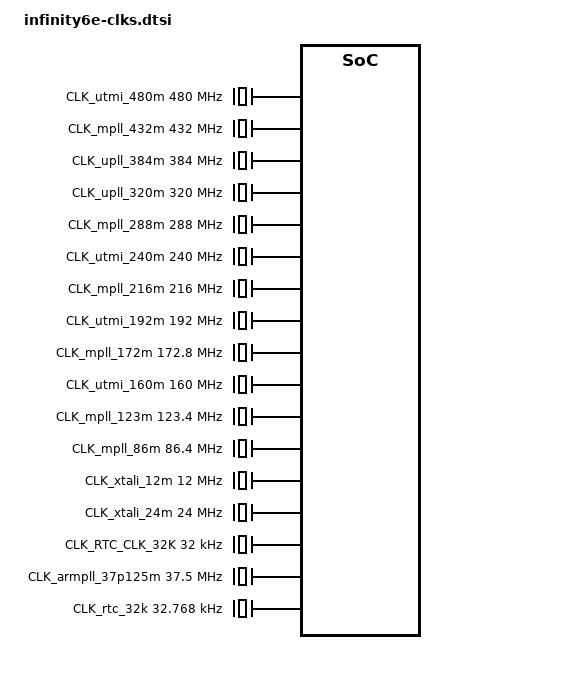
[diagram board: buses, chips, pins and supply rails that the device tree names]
/*
* infinity6e-clks.dtsi- Sigmastar
*
* Copyright (c) [2019~2020] SigmaStar Technology.
*
*
* This software is licensed under the terms of the GNU General Public
* License version 2, as published by the Free Software Foundation, and
* may be copied, distributed, and modified under those terms.
*
* This program is distributed in the hope that it will be useful,
* but WITHOUT ANY WARRANTY; without even the implied warranty of
* MERCHANTABILITY or FITNESS FOR A PARTICULAR PURPOSE.  See the
* GNU General Public License version 2 for more details.
*
*/
/* generated by CLK_DT_GEN_5.1 */
/* CLK FILENAME: I6e/iNfinity6e_Clock_Table_0903.xls */
/* REG FILENAME: I6e/iNfinity6e_reg_CLKGEN.xls, I6e/iNfinity6e_reg_pm_sleep.xls, I6e/iNfinity6e_reg_block.xls, I6e/iNfinity6e_reg_chiptop.xls */

CLK_VOID: CLK_VOID {
    #clock-cells = <0>;
    compatible = "fixed-clock";
    clock-frequency = <1>;
};

CLK_utmi_480m: CLK_utmi_480m {
    #clock-cells = <0>;
    compatible = "fixed-clock";
    clock-frequency = <480000000>;
};

CLK_mpll_432m: CLK_mpll_432m {
    #clock-cells = <0>;
    compatible = "fixed-clock";
    clock-frequency = <432000000>;
};

CLK_upll_384m: CLK_upll_384m {
    #clock-cells = <0>;
    compatible = "fixed-clock";
    clock-frequency = <384000000>;
};

CLK_upll_320m: CLK_upll_320m {
    #clock-cells = <0>;
    compatible = "fixed-clock";
    clock-frequency = <320000000>;
};

CLK_mpll_288m: CLK_mpll_288m {
    #clock-cells = <0>;
    compatible = "fixed-clock";
    clock-frequency = <288000000>;
};

CLK_utmi_240m: CLK_utmi_240m {
    #clock-cells = <0>;
    compatible = "fixed-clock";
    clock-frequency = <240000000>;
};

CLK_mpll_216m: CLK_mpll_216m {
    #clock-cells = <0>;
    compatible = "fixed-clock";
    clock-frequency = <216000000>;
};

CLK_utmi_192m: CLK_utmi_192m {
    #clock-cells = <0>;
    compatible = "fixed-clock";
    clock-frequency = <192000000>;
};

CLK_mpll_172m: CLK_mpll_172m {
    #clock-cells = <0>;
    compatible = "fixed-clock";
    clock-frequency = <172800000>;
};

CLK_utmi_160m: CLK_utmi_160m {
    #clock-cells = <0>;
    compatible = "fixed-clock";
    clock-frequency = <160000000>;
};

CLK_mpll_123m: CLK_mpll_123m {
    #clock-cells = <0>;
    compatible = "fixed-clock";
    clock-frequency = <123400000>;
};

CLK_mpll_86m: CLK_mpll_86m {
    #clock-cells = <0>;
    compatible = "fixed-clock";
    clock-frequency = <86400000>;
};

CLK_mpll_288m_div2: CLK_mpll_288m_div2 {
    #clock-cells = <0>;
    compatible = "fixed-factor-clock";
    clocks = <&CLK_mpll_288m>;
    clock-div = <2>;
    clock-mult = <1>;
};

CLK_mpll_288m_div4: CLK_mpll_288m_div4 {
    #clock-cells = <0>;
    compatible = "fixed-factor-clock";
    clocks = <&CLK_mpll_288m>;
    clock-div = <4>;
    clock-mult = <1>;
};

CLK_mpll_288m_div8: CLK_mpll_288m_div8 {
    #clock-cells = <0>;
    compatible = "fixed-factor-clock";
    clocks = <&CLK_mpll_288m>;
    clock-div = <8>;
    clock-mult = <1>;
};

CLK_mpll_216m_div2: CLK_mpll_216m_div2 {
    #clock-cells = <0>;
    compatible = "fixed-factor-clock";
    clocks = <&CLK_mpll_216m>;
    clock-div = <2>;
    clock-mult = <1>;
};

CLK_mpll_216m_div4: CLK_mpll_216m_div4 {
    #clock-cells = <0>;
    compatible = "fixed-factor-clock";
    clocks = <&CLK_mpll_216m>;
    clock-div = <4>;
    clock-mult = <1>;
};

CLK_mpll_216m_div8: CLK_mpll_216m_div8 {
    #clock-cells = <0>;
    compatible = "fixed-factor-clock";
    clocks = <&CLK_mpll_216m>;
    clock-div = <8>;
    clock-mult = <1>;
};

CLK_mpll_123m_div2: CLK_mpll_123m_div2 {
    #clock-cells = <0>;
    compatible = "fixed-factor-clock";
    clocks = <&CLK_mpll_123m>;
    clock-div = <2>;
    clock-mult = <1>;
};

CLK_mpll_86m_div2: CLK_mpll_86m_div2 {
    #clock-cells = <0>;
    compatible = "fixed-factor-clock";
    clocks = <&CLK_mpll_86m>;
    clock-div = <2>;
    clock-mult = <1>;
};

CLK_mpll_86m_div4: CLK_mpll_86m_div4 {
    #clock-cells = <0>;
    compatible = "fixed-factor-clock";
    clocks = <&CLK_mpll_86m>;
    clock-div = <4>;
    clock-mult = <1>;
};

CLK_mpll_86m_div16: CLK_mpll_86m_div16 {
    #clock-cells = <0>;
    compatible = "fixed-factor-clock";
    clocks = <&CLK_mpll_86m>;
    clock-div = <16>;
    clock-mult = <1>;
};

CLK_utmi_192m_div4: CLK_utmi_192m_div4 {
    #clock-cells = <0>;
    compatible = "fixed-factor-clock";
    clocks = <&CLK_utmi_192m>;
    clock-div = <4>;
    clock-mult = <1>;
};

CLK_utmi_160m_div4: CLK_utmi_160m_div4 {
    #clock-cells = <0>;
    compatible = "fixed-factor-clock";
    clocks = <&CLK_utmi_160m>;
    clock-div = <4>;
    clock-mult = <1>;
};

CLK_utmi_160m_div5: CLK_utmi_160m_div5 {
    #clock-cells = <0>;
    compatible = "fixed-factor-clock";
    clocks = <&CLK_utmi_160m>;
    clock-div = <5>;
    clock-mult = <1>;
};

CLK_utmi_160m_div8: CLK_utmi_160m_div8 {
    #clock-cells = <0>;
    compatible = "fixed-factor-clock";
    clocks = <&CLK_utmi_160m>;
    clock-div = <8>;
    clock-mult = <1>;
};

CLK_xtali_12m: CLK_xtali_12m {
    #clock-cells = <0>;
    compatible = "fixed-clock";
    clock-frequency = <12000000>;
};

CLK_xtali_12m_div2: CLK_xtali_12m_div2 {
    #clock-cells = <0>;
    compatible = "fixed-factor-clock";
    clocks = <&CLK_xtali_12m>;
    clock-div = <2>;
    clock-mult = <1>;
};

CLK_xtali_12m_div4: CLK_xtali_12m_div4 {
    #clock-cells = <0>;
    compatible = "fixed-factor-clock";
    clocks = <&CLK_xtali_12m>;
    clock-div = <4>;
    clock-mult = <1>;
};

CLK_xtali_12m_div8: CLK_xtali_12m_div8 {
    #clock-cells = <0>;
    compatible = "fixed-factor-clock";
    clocks = <&CLK_xtali_12m>;
    clock-div = <8>;
    clock-mult = <1>;
};

CLK_xtali_12m_div16: CLK_xtali_12m_div16 {
    #clock-cells = <0>;
    compatible = "fixed-factor-clock";
    clocks = <&CLK_xtali_12m>;
    clock-div = <16>;
    clock-mult = <1>;
};

CLK_xtali_12m_div40: CLK_xtali_12m_div40 {
    #clock-cells = <0>;
    compatible = "fixed-factor-clock";
    clocks = <&CLK_xtali_12m>;
    clock-div = <40>;
    clock-mult = <1>;
};

CLK_xtali_12m_div64: CLK_xtali_12m_div64 {
    #clock-cells = <0>;
    compatible = "fixed-factor-clock";
    clocks = <&CLK_xtali_12m>;
    clock-div = <64>;
    clock-mult = <1>;
};

CLK_xtali_12m_div128: CLK_xtali_12m_div128 {
    #clock-cells = <0>;
    compatible = "fixed-factor-clock";
    clocks = <&CLK_xtali_12m>;
    clock-div = <128>;
    clock-mult = <1>;
};

CLK_xtali_24m: CLK_xtali_24m {
    #clock-cells = <0>;
    compatible = "fixed-clock";
    clock-frequency = <24000000>;
};

CLK_RTC_CLK_32K: CLK_RTC_CLK_32K {
    #clock-cells = <0>;
    compatible = "fixed-clock";
    clock-frequency = <32000>;
};

CLK_pm_riu_w_clk_in: CLK_pm_riu_w_clk_in {
    #clock-cells = <0>;
    compatible = "fixed-clock";
    clock-frequency = <108000000>;
};

CLK_miupll_clk: CLK_miupll_clk {
    #clock-cells = <0>;
    compatible = "fixed-clock";
    clock-frequency = <400000000>;
};

CLK_ddrpll_clk: CLK_ddrpll_clk {
    #clock-cells = <0>;
    compatible = "fixed-clock";
    clock-frequency = <2133000000>;
};

CLK_lpll_clk: CLK_lpll_clk {
    #clock-cells = <0>;
    compatible = "fixed-clock";
    clock-frequency = <100000000>;
};

CLK_ven_pll: CLK_ven_pll {
    #clock-cells = <0>;
    compatible = "sstar,complex-clock";
    clocks = <&CLK_xtali_24m>;
};
CLK_ven_pll_div6: CLK_ven_pll_div6 {
    #clock-cells = <0>;
    compatible = "fixed-clock";
    clock-frequency = <104000000>;
};

CLK_lpll_div2: CLK_lpll_div2 {
    #clock-cells = <0>;
    compatible = "fixed-clock";
    clock-frequency = <50000000>;
};

CLK_lpll_div4: CLK_lpll_div4 {
    #clock-cells = <0>;
    compatible = "fixed-clock";
    clock-frequency = <25000000>;
};

CLK_lpll_div8: CLK_lpll_div8 {
    #clock-cells = <0>;
    compatible = "fixed-clock";
    clock-frequency = <12500000>;
};

CLK_armpll_37p125m: CLK_armpll_37p125m {
    #clock-cells = <0>;
    compatible = "fixed-clock";
    clock-frequency = <37500000>;
};

CLK_riu_w_clk_in: CLK_riu_w_clk_in {
    #clock-cells = <0>;
    compatible = "fixed-factor-clock";
    clocks = <&CLK_mcu>;
    clock-div = <1>;
    clock-mult = <1>;
};

CLK_riu_w_clk_top: CLK_riu_w_clk_top {
    #clock-cells = <0>;
    compatible = "fixed-factor-clock";
    clocks = <&CLK_mcu>;
    clock-div = <1>;
    clock-mult = <1>;
};

CLK_riu_w_clk_sc_gp: CLK_riu_w_clk_sc_gp {
    #clock-cells = <0>;
    compatible = "fixed-factor-clock";
    clocks = <&CLK_mcu>;
    clock-div = <1>;
    clock-mult = <1>;
};

CLK_riu_w_clk_vhe_gp: CLK_riu_w_clk_vhe_gp {
    #clock-cells = <0>;
    compatible = "fixed-factor-clock";
    clocks = <&CLK_mcu>;
    clock-div = <1>;
    clock-mult = <1>;
};

CLK_riu_w_clk_hemcu_gp: CLK_riu_w_clk_hemcu_gp {
    #clock-cells = <0>;
    compatible = "fixed-factor-clock";
    clocks = <&CLK_mcu>;
    clock-div = <1>;
    clock-mult = <1>;
};

CLK_riu_w_clk_mipi_if_gp: CLK_riu_w_clk_mipi_if_gp {
    #clock-cells = <0>;
    compatible = "fixed-factor-clock";
    clocks = <&CLK_mcu>;
    clock-div = <1>;
    clock-mult = <1>;
};

CLK_riu_w_clk_mcu_if_gp: CLK_riu_w_clk_mcu_if_gp {
    #clock-cells = <0>;
    compatible = "fixed-factor-clock";
    clocks = <&CLK_mcu>;
    clock-div = <1>;
    clock-mult = <1>;
};

CLK_fuart0_synth_out: CLK_fuart0_synth_out {
    #clock-cells = <0>;
    compatible = "fixed-clock";
    clock-frequency = <432000000>;
};

CLK_miu_p: CLK_miu_p {
    #clock-cells = <0>;
    compatible = "fixed-factor-clock";
    clocks = <&CLK_miu>;
    clock-div = <1>;
    clock-mult = <1>;
};

CLK_mspi0_p: CLK_mspi0_p {
    #clock-cells = <0>;
    compatible = "fixed-factor-clock";
    clocks = <&CLK_mspi0>;
    clock-div = <1>;
    clock-mult = <1>;
};

CLK_mspi1_p: CLK_mspi1_p {
    #clock-cells = <0>;
    compatible = "fixed-factor-clock";
    clocks = <&CLK_mspi1>;
    clock-div = <1>;
    clock-mult = <1>;
};

CLK_miu_vhe_gp_p: CLK_miu_vhe_gp_p {
    #clock-cells = <0>;
    compatible = "fixed-factor-clock";
    clocks = <&CLK_miu>;
    clock-div = <1>;
    clock-mult = <1>;
};

CLK_miu_sc_gp_p: CLK_miu_sc_gp_p {
    #clock-cells = <0>;
    compatible = "fixed-factor-clock";
    clocks = <&CLK_miu>;
    clock-div = <1>;
    clock-mult = <1>;
};

CLK_mcu_p: CLK_mcu_p {
    #clock-cells = <0>;
    compatible = "fixed-factor-clock";
    clocks = <&CLK_mcu>;
    clock-div = <1>;
    clock-mult = <1>;
};

CLK_fclk1_p: CLK_fclk1_p {
    #clock-cells = <0>;
    compatible = "fixed-factor-clock";
    clocks = <&CLK_fclk1>;
    clock-div = <1>;
    clock-mult = <1>;
};

/*
CLK_fclk2_p: CLK_fclk2_p {
    #clock-cells = <0>;
    compatible = "fixed-factor-clock";
    clocks = <&CLK_fclk2>;
    clock-div = <1>;
    clock-mult = <1>;
};
*/

CLK_sdio_p: CLK_sdio_p {
    #clock-cells = <0>;
    compatible = "fixed-factor-clock";
    clocks = <&CLK_sdio>;
    clock-div = <1>;
    clock-mult = <1>;
};

CLK_tck_buf: CLK_tck_buf {
    #clock-cells = <0>;
    compatible = "fixed-clock";
    clock-frequency = <50000000>;
};

CLK_eth_buf: CLK_eth_buf {
    #clock-cells = <0>;
    compatible = "fixed-clock";
    clock-frequency = <125000000>;
};

CLK_rmii_buf: CLK_rmii_buf {
    #clock-cells = <0>;
    compatible = "fixed-clock";
    clock-frequency = <125000000>;
};

CLK_emac_testrx125_in_lan: CLK_emac_testrx125_in_lan {
    #clock-cells = <0>;
    compatible = "fixed-clock";
    clock-frequency = <125000000>;
};

/*
CLK_imi: CLK_imi {
    #clock-cells = <0>;
    compatible = "fixed-factor-clock";
    clocks = <&CLK_miu_p>;
    clock-div = <1>;
    clock-mult = <1>;
};

CLK_sdio: CLK_sdio {
    #clock-cells = <0>;
    compatible = "fixed-factor-clock";
    clocks = <&CLK_sdio_p>;
    clock-div = <1>;
    clock-mult = <1>;
};
*/
CLK_gop0: CLK_gop0 {
    #clock-cells = <0>;
    compatible = "fixed-factor-clock";
    clocks = <&CLK_fclk1_p>;
    clock-div = <1>;
    clock-mult = <1>;
};
/*
CLK_gop1: CLK_gop1 {
    #clock-cells = <0>;
    compatible = "fixed-factor-clock";
    clocks = <&CLK_fclk1_p>;
    clock-div = <1>;
    clock-mult = <1>;
};

CLK_gop2: CLK_gop2 {
    #clock-cells = <0>;
    compatible = "fixed-factor-clock";
    clocks = <&CLK_fclk2_p>;
    clock-div = <1>;
    clock-mult = <1>;
};

*/
CLK_rtc_32k: CLK_rtc_32k {
    #clock-cells = <0>;
    compatible = "fixed-clock";
    clock-frequency = <32768>;
};

CLK_fro: CLK_fro {
    #clock-cells = <0>;
    compatible = "fixed-clock";
    clock-frequency = <48000000>;
};

CLK_fro_div2: CLK_fro_div2 {
    #clock-cells = <0>;
    compatible = "fixed-factor-clock";
    clocks = <&CLK_fro>;
    clock-div = <2>;
    clock-mult = <1>;
};

CLK_fro_div8: CLK_fro_div8 {
    #clock-cells = <0>;
    compatible = "fixed-factor-clock";
    clocks = <&CLK_fro>;
    clock-div = <8>;
    clock-mult = <1>;
};

CLK_fro_div16: CLK_fro_div16 {
    #clock-cells = <0>;
    compatible = "fixed-factor-clock";
    clocks = <&CLK_fro>;
    clock-div = <16>;
    clock-mult = <1>;
};

CLK_cpupll_clk: CLK_cpupll_clk {
    #clock-cells = <0>;
    compatible = "sstar,complex-clock";
    clocks = <&CLK_mpll_432m>;
};

CLK_utmi: CLK_utmi {
    #clock-cells = <0>;
//    compatible = "sstar,complex-clock";
//    clocks = <&CLK_upll>;
    compatible = "fixed-clock";
    clock-frequency = <480000000>;
};

CLK_bach: CLK_bach {
    #clock-cells = <0>;
    compatible = "sstar,composite-clock";
    clocks = <&CLK_upll_384m>;
    reg = <REG_CKG_BACH_384M_BASE 0x4>;
    //mux-shift = <2>;  //2+REG_CKG_MIU_OFFSET
    //mux-width = <2>;
    gate-shift = <7>;  //0+REG_CKG_MIU_OFFSET
    //glitch-shift = <4>;  //4+REG_CKG_MIU_OFFSET
    //auto-enable = <0>;
};

CLK_miu: CLK_miu {
    #clock-cells = <0>;
    compatible = "sstar,composite-clock";
    clocks = <&CLK_mpll_216m>,<&CLK_miupll_clk>,<&CLK_VOID>,<&CLK_VOID>;
    reg = <REG_CKG_MIU_BASE 0x4>;
    mux-shift = <2>;  //2+REG_CKG_MIU_OFFSET
    mux-width = <2>;
    gate-shift = <0>;  //0+REG_CKG_MIU_OFFSET
    glitch-shift = <4>;  //4+REG_CKG_MIU_OFFSET
    auto-enable = <1>;
};

CLK_miu_boot: CLK_miu_boot {
    #clock-cells = <0>;
    compatible = "sstar,composite-clock";
    clocks = <&CLK_xtali_12m>,<&CLK_miu>;
    reg = <REG_CKG_MIU_BASE 0x4>;
    mux-shift = <2>;  //2+REG_CKG_MIU_OFFSET
    mux-width = <1>;
    gate-shift = <0>;  //0+REG_CKG_MIU_OFFSET
    auto-enable = <1>;
};

CLK_ddr_syn: CLK_ddr_syn {
    #clock-cells = <0>;
    compatible = "sstar,composite-clock";
    clocks = <&CLK_mpll_432m>,<&CLK_mpll_216m>,<&CLK_xtali_12m>,<&CLK_VOID>;
    reg = <REG_CKG_DDR_SYN_BASE 0x4>;
    mux-shift = <2>;  //2+REG_CKG_DDR_SYN_OFFSET
    mux-width = <2>;
    gate-shift = <0>;  //0+REG_CKG_DDR_SYN_OFFSET
    auto-enable = <1>;
};

CLK_miu_rec: CLK_miu_rec {
    #clock-cells = <0>;
    compatible = "sstar,composite-clock";
    clocks = <&CLK_xtali_12m_div8>,<&CLK_xtali_12m_div16>,<&CLK_xtali_12m_div64>,<&CLK_xtali_12m_div128>;
    reg = <REG_CKG_MIU_REC_BASE 0x4>;
    mux-shift = <2>;  //2+REG_CKG_MIU_REC_OFFSET
    mux-width = <2>;
    gate-shift = <0>;  //0+REG_CKG_MIU_REC_OFFSET
    auto-enable = <1>;
};

CLK_mcu: CLK_mcu {
    #clock-cells = <0>;
    compatible = "sstar,composite-clock";
    clocks = <&CLK_mpll_216m>,<&CLK_mpll_432m>,<&CLK_upll_384m>,<&CLK_mpll_216m_div2>;
    reg = <REG_CKG_MCU_BASE 0x4>;
    mux-shift = <2>;  //2+REG_CKG_MCU_OFFSET
    mux-width = <2>;
    gate-shift = <0>;  //0+REG_CKG_MCU_OFFSET
    glitch-shift = <4>;  //4+REG_CKG_MCU_OFFSET
    auto-enable = <1>;
};

CLK_riubrdg: CLK_riubrdg {
    #clock-cells = <0>;
    compatible = "sstar,composite-clock";
    clocks = <&CLK_mcu_p>,<&CLK_VOID>,<&CLK_VOID>,<&CLK_VOID>;
    reg = <REG_CKG_RIUBRDG_BASE 0x4>;
    mux-shift = <10>;  //2+REG_CKG_RIUBRDG_OFFSET
    mux-width = <2>;
    gate-shift = <8>;  //0+REG_CKG_RIUBRDG_OFFSET
    auto-enable = <1>;
};

CLK_bdma: CLK_bdma {
    #clock-cells = <0>;
    compatible = "sstar,composite-clock";
    clocks = <&CLK_miu_p>,<&CLK_VOID>,<&CLK_VOID>,<&CLK_VOID>;
    reg = <REG_CKG_BDMA_BASE 0x4>;
    mux-shift = <2>;  //2+REG_CKG_BDMA_OFFSET
    mux-width = <2>;
    gate-shift = <0>;  //0+REG_CKG_BDMA_OFFSET
    auto-enable = <0>;
};

CLK_spi_arb: CLK_spi_arb {
    #clock-cells = <0>;
    compatible = "sstar,composite-clock";
    clocks = <&CLK_mpll_216m>,<&CLK_mpll_216m_div2>,<&CLK_mpll_86m>,<&CLK_miu_p>;
    reg = <REG_CKG_SPI_ARB_BASE 0x4>;
    mux-shift = <2>;  //2+REG_CKG_SPI_ARB_OFFSET
    mux-width = <2>;
    gate-shift = <0>;  //0+REG_CKG_SPI_ARB_OFFSET
    glitch-shift = <4>;  //4+REG_CKG_SPI_ARB_OFFSET
    auto-enable = <1>;
};

CLK_spi_flash: CLK_spi_flash {
    #clock-cells = <0>;
    compatible = "sstar,composite-clock";
    clocks = <&CLK_xtali_12m>,<&CLK_mpll_216m_div8>,<&CLK_mpll_288m_div8>,<&CLK_ven_pll_div6>,<&CLK_mpll_216m_div4>,<&CLK_mpll_288m_div4>,<&CLK_mpll_86m>,<&CLK_mpll_216m_div2>;
    reg = <REG_CKG_SPI_FLASH_BASE 0x4>;
    mux-shift = <2>;  //2+REG_CKG_SPI_FLASH_OFFSET
    mux-width = <3>;
    gate-shift = <0>;  //0+REG_CKG_SPI_FLASH_OFFSET
    glitch-shift = <5>;  //5+REG_CKG_SPI_FLASH_OFFSET
    auto-enable = <1>;
};

CLK_pwm: CLK_pwm {
    #clock-cells = <0>;
    compatible = "sstar,composite-clock";
    clocks = <&CLK_xtali_12m>,<&CLK_xtali_12m_div2>,<&CLK_xtali_12m_div4>,<&CLK_xtali_12m_div8>,<&CLK_xtali_24m>,<&CLK_mpll_86m>,<&CLK_VOID>,<&CLK_VOID>;
    reg = <REG_CKG_PWM_BASE 0x4>;
    mux-shift = <10>;  //2+REG_CKG_PWM_OFFSET
    mux-width = <3>;
    gate-shift = <8>;  //0+REG_CKG_PWM_OFFSET
    auto-enable = <0>;
};

CLK_uart0: CLK_uart0 {
    #clock-cells = <0>;
    compatible = "sstar,composite-clock";
    clocks = <&CLK_mpll_172m>,<&CLK_mpll_288m_div2>,<&CLK_xtali_12m>,<&CLK_VOID>;
    reg = <REG_CKG_UART0_BASE 0x4>;
    mux-shift = <2>;  //2+REG_CKG_UART0_OFFSET
    mux-width = <2>;
    gate-shift = <0>;  //0+REG_CKG_UART0_OFFSET
    auto-enable = <0>;
};

CLK_uart1: CLK_uart1 {
    #clock-cells = <0>;
    compatible = "sstar,composite-clock";
    clocks = <&CLK_mpll_172m>,<&CLK_mpll_288m_div2>,<&CLK_xtali_12m>,<&CLK_VOID>;
    reg = <REG_CKG_UART1_BASE 0x4>;
    mux-shift = <10>;  //2+REG_CKG_UART1_OFFSET
    mux-width = <2>;
    gate-shift = <8>;  //0+REG_CKG_UART1_OFFSET
    auto-enable = <0>;
};

CLK_fuart0_synth_in: CLK_fuart0_synth_in {
    #clock-cells = <0>;
    compatible = "sstar,composite-clock";
    clocks = <&CLK_mpll_432m>,<&CLK_mpll_216m>,<&CLK_VOID>,<&CLK_VOID>;
    reg = <REG_CKG_FUART0_SYNTH_IN_BASE 0x4>;
    mux-shift = <6>;  //2+REG_CKG_FUART0_SYNTH_IN_OFFSET
    mux-width = <2>;
    gate-shift = <4>;  //0+REG_CKG_FUART0_SYNTH_IN_OFFSET
    auto-enable = <0>;
};

CLK_fuart: CLK_fuart {
    #clock-cells = <0>;
    compatible = "sstar,composite-clock";
    clocks = <&CLK_mpll_172m>,<&CLK_mpll_288m_div2>,<&CLK_xtali_12m>,<&CLK_fuart0_synth_out>;
    reg = <REG_CKG_FUART_BASE 0x4>;
    mux-shift = <2>;  //2+REG_CKG_FUART_OFFSET
    mux-width = <2>;
    gate-shift = <0>;  //0+REG_CKG_FUART_OFFSET
    auto-enable = <0>;
};

CLK_mspi0: CLK_mspi0 {
    #clock-cells = <0>;
    compatible = "sstar,composite-clock";
    clocks = <&CLK_mpll_216m_div2>,<&CLK_mpll_216m_div4>,<&CLK_xtali_12m>,<&CLK_mpll_288m_div2>;
    reg = <REG_CKG_MSPI0_BASE 0x4>;
    mux-shift = <2>;  //2+REG_CKG_MSPI0_OFFSET
    mux-width = <2>;
    gate-shift = <0>;  //0+REG_CKG_MSPI0_OFFSET
    auto-enable = <0>;
};

CLK_mspi1: CLK_mspi1 {
    #clock-cells = <0>;
    compatible = "sstar,composite-clock";
    clocks = <&CLK_mpll_216m_div2>,<&CLK_mpll_216m_div4>,<&CLK_xtali_12m>,<&CLK_mpll_288m_div2>;
    reg = <REG_CKG_MSPI1_BASE 0x4>;
    mux-shift = <10>;  //2+REG_CKG_MSPI1_OFFSET
    mux-width = <2>;
    gate-shift = <8>;  //0+REG_CKG_MSPI1_OFFSET
    auto-enable = <0>;
};

CLK_mspi: CLK_mspi {
    #clock-cells = <0>;
    compatible = "sstar,composite-clock";
    clocks = <&CLK_mspi0_p>,<&CLK_mspi1_p>;
    reg = <REG_CKG_MSPI_BASE 0x4>;
    mux-shift = <14>;  //2+REG_CKG_MSPI_OFFSET
    mux-width = <1>;
    gate-shift = <12>;  //0+REG_CKG_MSPI_OFFSET
    auto-enable = <0>;
};

CLK_miic0: CLK_miic0 {
    #clock-cells = <0>;
    compatible = "sstar,composite-clock";
    clocks = <&CLK_mpll_288m_div4>,<&CLK_mpll_216m_div4>,<&CLK_xtali_12m>,<&CLK_VOID>;
    reg = <REG_CKG_MIIC0_BASE 0x4>;
    mux-shift = <2>;  //2+REG_CKG_MIIC0_OFFSET
    mux-width = <2>;
    gate-shift = <0>;  //0+REG_CKG_MIIC0_OFFSET
    auto-enable = <0>;
};

CLK_miic1: CLK_miic1 {
    #clock-cells = <0>;
    compatible = "sstar,composite-clock";
    clocks = <&CLK_mpll_288m_div4>,<&CLK_mpll_216m_div4>,<&CLK_xtali_12m>,<&CLK_VOID>;
    reg = <REG_CKG_MIIC1_BASE 0x4>;
    mux-shift = <10>;  //2+REG_CKG_MIIC1_OFFSET
    mux-width = <2>;
    gate-shift = <8>;  //0+REG_CKG_MIIC1_OFFSET
    auto-enable = <0>;
};

CLK_miic2: CLK_miic2 {
    #clock-cells = <0>;
    compatible = "sstar,composite-clock";
    clocks = <&CLK_mpll_288m_div4>,<&CLK_mpll_216m_div4>,<&CLK_xtali_12m>,<&CLK_VOID>;
    reg = <REG_CKG_MIIC2_BASE 0x4>;
    mux-shift = <14>;  //2+REG_CKG_MIIC2_OFFSET
    mux-width = <2>;
    gate-shift = <12>;  //0+REG_CKG_MIIC2_OFFSET
    auto-enable = <0>;
};

CLK_bist: CLK_bist {
    #clock-cells = <0>;
    compatible = "sstar,composite-clock";
    clocks = <&CLK_mpll_172m>,<&CLK_mpll_216m_div2>,<&CLK_mpll_216m_div4>,<&CLK_xtali_12m>;
    reg = <REG_CKG_BIST_BASE 0x4>;
    mux-shift = <2>;  //2+REG_CKG_BIST_OFFSET
    mux-width = <2>;
    gate-shift = <0>;  //0+REG_CKG_BIST_OFFSET
    auto-enable = <0>;
};

CLK_pwr_ctl: CLK_pwr_ctl {
    #clock-cells = <0>;
    compatible = "sstar,composite-clock";
    clocks = <&CLK_xtali_12m_div16>,<&CLK_xtali_12m_div8>,<&CLK_xtali_12m>,<&CLK_VOID>;
    reg = <REG_CKG_PWR_CTL_BASE 0x4>;
    mux-shift = <2>;  //2+REG_CKG_PWR_CTL_OFFSET
    mux-width = <2>;
    gate-shift = <0>;  //0+REG_CKG_PWR_CTL_OFFSET
    auto-enable = <0>;
};

CLK_xtali: CLK_xtali {
    #clock-cells = <0>;
    compatible = "sstar,composite-clock";
    clocks = <&CLK_xtali_12m>,<&CLK_VOID>,<&CLK_VOID>,<&CLK_VOID>;
    reg = <REG_CKG_XTALI_BASE 0x4>;
    mux-shift = <2>;  //2+REG_CKG_XTALI_OFFSET
    mux-width = <2>;
    gate-shift = <0>;  //0+REG_CKG_XTALI_OFFSET
    auto-enable = <1>;
};

CLK_live: CLK_live {
    #clock-cells = <0>;
    compatible = "sstar,composite-clock";
    clocks = <&CLK_xtali_12m>,<&CLK_VOID>,<&CLK_VOID>,<&CLK_VOID>;
    reg = <REG_CKG_LIVE_BASE 0x4>;
    mux-shift = <10>;  //2+REG_CKG_LIVE_OFFSET
    mux-width = <2>;
    gate-shift = <8>;  //0+REG_CKG_LIVE_OFFSET
    auto-enable = <1>;
};

CLK_sr00_mclk: CLK_sr00_mclk {
    #clock-cells = <0>;
    compatible = "sstar,composite-clock";
    clocks = <&CLK_mpll_216m_div8>,<&CLK_mpll_288m_div4>,<&CLK_mpll_123m_div2>,<&CLK_mpll_216m_div4>,<&CLK_utmi_192m_div4>,<&CLK_mpll_86m_div2>,<&CLK_mpll_288m_div8>,<&CLK_xtali_24m>,<&CLK_mpll_86m_div4>,<&CLK_xtali_12m>,<&CLK_mpll_86m_div16>,<&CLK_lpll_clk>,<&CLK_lpll_div2>,<&CLK_lpll_div4>,<&CLK_lpll_div8>,<&CLK_armpll_37p125m>;
    reg = <REG_CKG_SR00_MCLK_BASE 0x4>;
    mux-shift = <10>;  //2+REG_CKG_SR00_MCLK_OFFSET
    mux-width = <4>;
    gate-shift = <8>;  //0+REG_CKG_SR00_MCLK_OFFSET
    auto-enable = <0>;
};

CLK_sr01_mclk: CLK_sr01_mclk {
    #clock-cells = <0>;
    compatible = "sstar,composite-clock";
    clocks = <&CLK_mpll_216m_div8>,<&CLK_mpll_288m_div4>,<&CLK_mpll_123m_div2>,<&CLK_mpll_216m_div4>,<&CLK_utmi_192m_div4>,<&CLK_mpll_86m_div2>,<&CLK_mpll_288m_div8>,<&CLK_xtali_24m>,<&CLK_mpll_86m_div4>,<&CLK_xtali_12m>,<&CLK_mpll_86m_div16>,<&CLK_lpll_clk>,<&CLK_lpll_div2>,<&CLK_lpll_div4>,<&CLK_lpll_div8>,<&CLK_armpll_37p125m>;
    reg = <REG_CKG_SR01_MCLK_BASE 0x4>;
    mux-shift = <2>;  //2+REG_CKG_SR01_MCLK_OFFSET
    mux-width = <4>;
    gate-shift = <0>;  //0+REG_CKG_SR01_MCLK_OFFSET
    auto-enable = <0>;
};

CLK_sr1_mclk: CLK_sr1_mclk {
    #clock-cells = <0>;
    compatible = "sstar,composite-clock";
    clocks = <&CLK_mpll_216m_div8>,<&CLK_mpll_288m_div4>,<&CLK_mpll_123m_div2>,<&CLK_mpll_216m_div4>,<&CLK_utmi_192m_div4>,<&CLK_mpll_86m_div2>,<&CLK_mpll_288m_div8>,<&CLK_xtali_24m>,<&CLK_mpll_86m_div4>,<&CLK_xtali_12m>,<&CLK_mpll_86m_div16>,<&CLK_lpll_clk>,<&CLK_lpll_div2>,<&CLK_lpll_div4>,<&CLK_lpll_div8>,<&CLK_armpll_37p125m>;
    reg = <REG_CKG_SR1_MCLK_BASE 0x4>;
    mux-shift = <10>;  //2+REG_CKG_SR1_MCLK_OFFSET
    mux-width = <4>;
    gate-shift = <8>;  //0+REG_CKG_SR1_MCLK_OFFSET
    auto-enable = <0>;
};

CLK_bist_pm: CLK_bist_pm {
    #clock-cells = <0>;
    compatible = "sstar,composite-clock";
    clocks = <&CLK_mpll_216m_div2>,<&CLK_mpll_216m_div4>,<&CLK_mpll_216m_div8>,<&CLK_xtali_12m>;
    reg = <REG_CKG_BIST_PM_BASE 0x4>;
    mux-shift = <10>;  //2+REG_CKG_BIST_PM_OFFSET
    mux-width = <2>;
    gate-shift = <8>;  //0+REG_CKG_BIST_PM_OFFSET
    auto-enable = <0>;
};

CLK_bist_ipu_gp: CLK_bist_ipu_gp {
    #clock-cells = <0>;
    compatible = "sstar,composite-clock";
    clocks = <&CLK_mpll_288m>,<&CLK_mpll_216m>,<&CLK_mpll_172m>,<&CLK_mpll_216m_div2>,<&CLK_mpll_86m>,<&CLK_mpll_216m_div4>,<&CLK_mpll_216m_div8>,<&CLK_xtali_12m>;
    reg = <REG_CKG_BIST_IPU_GP_BASE 0x4>;
    mux-shift = <2>;  //2+REG_CKG_BIST_IPU_GP_OFFSET
    mux-width = <3>;
    gate-shift = <0>;  //0+REG_CKG_BIST_IPU_GP_OFFSET
    auto-enable = <1>;
};

CLK_ipu: CLK_ipu {
    #clock-cells = <0>;
    compatible = "sstar,composite-clock";
    clocks = <&CLK_xtali_12m>,<&CLK_utmi_480m>,<&CLK_mpll_432m>,<&CLK_upll_384m>,<&CLK_upll_320m>,<&CLK_utmi_240m>,<&CLK_mpll_216m>,<&CLK_mpll_123m>;
    reg = <REG_CKG_IPU_BASE 0x4>;
    mux-shift = <2>;  //2+REG_CKG_IPU_OFFSET
    mux-width = <3>;
    gate-shift = <0>;  //0+REG_CKG_IPU_OFFSET
    auto-enable = <0>;
};

CLK_ipuff: CLK_ipuff {
    #clock-cells = <0>;
    compatible = "sstar,composite-clock";
    clocks = <&CLK_mpll_432m>,<&CLK_upll_384m>,<&CLK_upll_320m>,<&CLK_utmi_240m>;
    reg = <REG_CKG_IPUFF_BASE 0x4>;
    mux-shift = <10>;  //2+REG_CKG_IPUFF_OFFSET
    mux-width = <2>;
    gate-shift = <8>;  //0+REG_CKG_IPUFF_OFFSET
    auto-enable = <0>;
};

CLK_bist_usb30_gp: CLK_bist_usb30_gp {
    #clock-cells = <0>;
    compatible = "sstar,composite-clock";
    clocks = <&CLK_mpll_172m>,<&CLK_mpll_216m_div2>,<&CLK_mpll_216m_div4>,<&CLK_xtali_12m>;
    reg = <REG_CKG_BIST_USB30_GP_BASE 0x4>;
    mux-shift = <10>;  //2+REG_CKG_BIST_USB30_GP_OFFSET
    mux-width = <2>;
    gate-shift = <8>;  //0+REG_CKG_BIST_USB30_GP_OFFSET
    auto-enable = <0>;
};

CLK_csi_mac_lptx_top_i_m00: CLK_csi_mac_lptx_top_i_m00 {
    #clock-cells = <0>;
    compatible = "sstar,composite-clock";
    clocks = <&CLK_mpll_216m>,<&CLK_utmi_240m>,<&CLK_mpll_172m>,<&CLK_mpll_288m_div2>,<&CLK_mpll_86m>,<&CLK_utmi_160m_div4>,<&CLK_VOID>,<&CLK_VOID>;
    reg = <REG_CKG_CSI_MAC_LPTX_TOP_I_M00_BASE 0x4>;
    mux-shift = <2>;  //2+REG_CKG_CSI_MAC_LPTX_TOP_I_M00_OFFSET
    mux-width = <3>;
    gate-shift = <0>;  //0+REG_CKG_CSI_MAC_LPTX_TOP_I_M00_OFFSET
    auto-enable = <0>;
};

CLK_csi_mac_top_i_m00: CLK_csi_mac_top_i_m00 {
    #clock-cells = <0>;
    compatible = "sstar,composite-clock";
    clocks = <&CLK_mpll_216m>,<&CLK_utmi_240m>,<&CLK_mpll_172m>,<&CLK_mpll_288m_div2>,<&CLK_mpll_86m>,<&CLK_utmi_160m_div4>,<&CLK_VOID>,<&CLK_VOID>;
    reg = <REG_CKG_CSI_MAC_TOP_I_M00_BASE 0x4>;
    mux-shift = <10>;  //2+REG_CKG_CSI_MAC_TOP_I_M00_OFFSET
    mux-width = <3>;
    gate-shift = <8>;  //0+REG_CKG_CSI_MAC_TOP_I_M00_OFFSET
    auto-enable = <0>;
};

CLK_ns_top_i_m00: CLK_ns_top_i_m00 {
    #clock-cells = <0>;
    compatible = "sstar,composite-clock";
    clocks = <&CLK_mpll_216m>,<&CLK_utmi_240m>,<&CLK_mpll_172m>,<&CLK_mpll_288m_div2>,<&CLK_mpll_86m>,<&CLK_utmi_160m_div4>,<&CLK_VOID>,<&CLK_VOID>;
    reg = <REG_CKG_NS_TOP_I_M00_BASE 0x4>;
    mux-shift = <2>;  //2+REG_CKG_NS_TOP_I_M00_OFFSET
    mux-width = <3>;
    gate-shift = <0>;  //0+REG_CKG_NS_TOP_I_M00_OFFSET
    auto-enable = <0>;
};

CLK_csi_mac_lptx_top_i_m01: CLK_csi_mac_lptx_top_i_m01 {
    #clock-cells = <0>;
    compatible = "sstar,composite-clock";
    clocks = <&CLK_mpll_216m>,<&CLK_utmi_240m>,<&CLK_mpll_172m>,<&CLK_mpll_288m_div2>,<&CLK_mpll_86m>,<&CLK_utmi_160m_div4>,<&CLK_VOID>,<&CLK_VOID>;
    reg = <REG_CKG_CSI_MAC_LPTX_TOP_I_M01_BASE 0x4>;
    mux-shift = <10>;  //2+REG_CKG_CSI_MAC_LPTX_TOP_I_M01_OFFSET
    mux-width = <3>;
    gate-shift = <8>;  //0+REG_CKG_CSI_MAC_LPTX_TOP_I_M01_OFFSET
    auto-enable = <0>;
};

CLK_csi_mac_top_i_m01: CLK_csi_mac_top_i_m01 {
    #clock-cells = <0>;
    compatible = "sstar,composite-clock";
    clocks = <&CLK_mpll_216m>,<&CLK_utmi_240m>,<&CLK_mpll_172m>,<&CLK_mpll_288m_div2>,<&CLK_mpll_86m>,<&CLK_utmi_160m_div4>,<&CLK_VOID>,<&CLK_VOID>;
    reg = <REG_CKG_CSI_MAC_TOP_I_M01_BASE 0x4>;
    mux-shift = <2>;  //2+REG_CKG_CSI_MAC_TOP_I_M01_OFFSET
    mux-width = <3>;
    gate-shift = <0>;  //0+REG_CKG_CSI_MAC_TOP_I_M01_OFFSET
    auto-enable = <0>;
};

CLK_ns_top_i_m01: CLK_ns_top_i_m01 {
    #clock-cells = <0>;
    compatible = "sstar,composite-clock";
    clocks = <&CLK_mpll_216m>,<&CLK_utmi_240m>,<&CLK_mpll_172m>,<&CLK_mpll_288m_div2>,<&CLK_mpll_86m>,<&CLK_utmi_160m_div4>,<&CLK_VOID>,<&CLK_VOID>;
    reg = <REG_CKG_NS_TOP_I_M01_BASE 0x4>;
    mux-shift = <10>;  //2+REG_CKG_NS_TOP_I_M01_OFFSET
    mux-width = <3>;
    gate-shift = <8>;  //0+REG_CKG_NS_TOP_I_M01_OFFSET
    auto-enable = <0>;
};

CLK_csi_mac_lptx_top_i_m1: CLK_csi_mac_lptx_top_i_m1 {
    #clock-cells = <0>;
    compatible = "sstar,composite-clock";
    clocks = <&CLK_mpll_216m>,<&CLK_utmi_240m>,<&CLK_mpll_172m>,<&CLK_mpll_288m_div2>,<&CLK_mpll_86m>,<&CLK_utmi_160m_div4>,<&CLK_VOID>,<&CLK_VOID>;
    reg = <REG_CKG_CSI_MAC_LPTX_TOP_I_M1_BASE 0x4>;
    mux-shift = <2>;  //2+REG_CKG_CSI_MAC_LPTX_TOP_I_M1_OFFSET
    mux-width = <3>;
    gate-shift = <0>;  //0+REG_CKG_CSI_MAC_LPTX_TOP_I_M1_OFFSET
    auto-enable = <0>;
};

CLK_csi_mac_top_i_m1: CLK_csi_mac_top_i_m1 {
    #clock-cells = <0>;
    compatible = "sstar,composite-clock";
    clocks = <&CLK_mpll_216m>,<&CLK_utmi_240m>,<&CLK_mpll_172m>,<&CLK_mpll_288m_div2>,<&CLK_mpll_86m>,<&CLK_utmi_160m_div4>,<&CLK_VOID>,<&CLK_VOID>;
    reg = <REG_CKG_CSI_MAC_TOP_I_M1_BASE 0x4>;
    mux-shift = <10>;  //2+REG_CKG_CSI_MAC_TOP_I_M1_OFFSET
    mux-width = <3>;
    gate-shift = <8>;  //0+REG_CKG_CSI_MAC_TOP_I_M1_OFFSET
    auto-enable = <0>;
};

CLK_ns_top_i_m1: CLK_ns_top_i_m1 {
    #clock-cells = <0>;
    compatible = "sstar,composite-clock";
    clocks = <&CLK_mpll_216m>,<&CLK_utmi_240m>,<&CLK_mpll_172m>,<&CLK_mpll_288m_div2>,<&CLK_mpll_86m>,<&CLK_utmi_160m_div4>,<&CLK_VOID>,<&CLK_VOID>;
    reg = <REG_CKG_NS_TOP_I_M1_BASE 0x4>;
    mux-shift = <2>;  //2+REG_CKG_NS_TOP_I_M1_OFFSET
    mux-width = <3>;
    gate-shift = <0>;  //0+REG_CKG_NS_TOP_I_M1_OFFSET
    auto-enable = <0>;
};

CLK_mipi1_tx_csi: CLK_mipi1_tx_csi {
    #clock-cells = <0>;
    compatible = "sstar,composite-clock";
    clocks = <&CLK_lpll_clk>,<&CLK_utmi_160m>,<&CLK_mpll_288m_div2>,<&CLK_mpll_216m_div2>,<&CLK_mpll_216m>,<&CLK_utmi_240m>,<&CLK_mpll_288m>,<&CLK_upll_320m>;
    reg = <REG_CKG_MIPI1_TX_CSI_BASE 0x4>;
    mux-shift = <10>;  //2+REG_CKG_MIPI1_TX_CSI_OFFSET
    mux-width = <3>;
    gate-shift = <8>;  //0+REG_CKG_MIPI1_TX_CSI_OFFSET
    auto-enable = <0>;
};

CLK_bist_vhe_gp: CLK_bist_vhe_gp {
    #clock-cells = <0>;
    compatible = "sstar,composite-clock";
    clocks = <&CLK_mpll_288m>,<&CLK_mpll_216m>,<&CLK_mpll_172m>,<&CLK_mpll_216m_div2>,<&CLK_mpll_86m>,<&CLK_mpll_216m_div4>,<&CLK_mpll_216m_div8>,<&CLK_xtali_12m>;
    reg = <REG_CKG_BIST_VHE_GP_BASE 0x4>;
    mux-shift = <10>;  //2+REG_CKG_BIST_VHE_GP_OFFSET
    mux-width = <3>;
    gate-shift = <8>;  //0+REG_CKG_BIST_VHE_GP_OFFSET
    auto-enable = <0>;
};

CLK_vhe: CLK_vhe {
    #clock-cells = <0>;
    compatible = "sstar,composite-clock";
    clocks = <&CLK_ven_pll>,<&CLK_utmi_480m>,<&CLK_mpll_432m>,<&CLK_upll_384m>,<&CLK_upll_320m>,<&CLK_mpll_288m>,<&CLK_utmi_192m>,<&CLK_mpll_123m>;
    reg = <REG_CKG_VHE_BASE 0x4>;
    mux-shift = <2>;  //2+REG_CKG_VHE_OFFSET
    mux-width = <3>;
    gate-shift = <7>;  //0+REG_CKG_VHE_OFFSET
    auto-enable = <0>;
};

CLK_mfe: CLK_mfe {
    #clock-cells = <0>;
    compatible = "sstar,composite-clock";
    clocks = <&CLK_mpll_216m>,<&CLK_upll_384m>,<&CLK_upll_320m>,<&CLK_ven_pll>;
    reg = <REG_CKG_MFE_BASE 0x4>;
    mux-shift = <2>;  //2+REG_CKG_MFE_OFFSET
    mux-width = <2>;
    gate-shift = <0>;  //0+REG_CKG_MFE_OFFSET
    auto-enable = <0>;
};

CLK_xtali_sc_gp: CLK_xtali_sc_gp {
    #clock-cells = <0>;
    compatible = "sstar,composite-clock";
    clocks = <&CLK_xtali_12m>,<&CLK_VOID>,<&CLK_VOID>,<&CLK_VOID>;
    reg = <REG_CKG_XTALI_SC_GP_BASE 0x4>;
    mux-shift = <6>;  //2+REG_CKG_XTALI_SC_GP_OFFSET
    mux-width = <2>;
    gate-shift = <4>;  //0+REG_CKG_XTALI_SC_GP_OFFSET
    auto-enable = <1>;
};

CLK_bist_sc_gp: CLK_bist_sc_gp {
    #clock-cells = <0>;
    compatible = "sstar,composite-clock";
    clocks = <&CLK_mpll_288m>,<&CLK_mpll_216m>,<&CLK_mpll_172m>,<&CLK_mpll_216m_div2>,<&CLK_mpll_86m>,<&CLK_mpll_216m_div4>,<&CLK_mpll_216m_div8>,<&CLK_xtali_12m>;
    reg = <REG_CKG_BIST_SC_GP_BASE 0x4>;
    mux-shift = <2>;  //2+REG_CKG_BIST_SC_GP_OFFSET
    mux-width = <3>;
    gate-shift = <0>;  //0+REG_CKG_BIST_SC_GP_OFFSET
    auto-enable = <1>;
};

CLK_emac_ahb: CLK_emac_ahb {
    #clock-cells = <0>;
    compatible = "sstar,composite-clock";
    clocks = <&CLK_mpll_288m_div2>,<&CLK_mpll_123m>,<&CLK_mpll_86m>,<&CLK_emac_testrx125_in_lan>;
    reg = <REG_CKG_EMAC_AHB_BASE 0x4>;
    mux-shift = <2>;  //2+REG_CKG_EMAC_AHB_OFFSET
    mux-width = <2>;
    gate-shift = <0>;  //0+REG_CKG_EMAC_AHB_OFFSET
    auto-enable = <0>;
};

CLK_jpe: CLK_jpe {
    #clock-cells = <0>;
    compatible = "sstar,composite-clock";
    clocks = <&CLK_utmi_480m>,<&CLK_mpll_432m>,<&CLK_upll_384m>,<&CLK_upll_320m>,<&CLK_mpll_288m>,<&CLK_mpll_216m>,<&CLK_VOID>,<&CLK_VOID>;
    reg = <REG_CKG_JPE_BASE 0x4>;
    mux-shift = <2>;  //2+REG_CKG_JPE_OFFSET
    mux-width = <3>;
    gate-shift = <0>;  //0+REG_CKG_JPE_OFFSET
    auto-enable = <0>;
};

CLK_aesdma: CLK_aesdma {
    #clock-cells = <0>;
    compatible = "sstar,composite-clock";
    clocks = <&CLK_mpll_86m>,<&CLK_mpll_172m>,<&CLK_VOID>,<&CLK_VOID>;
    reg = <REG_CKG_AESDMA_BASE 0x4>;
    mux-shift = <2>;  //2+REG_CKG_AESDMA_OFFSET
    mux-width = <2>;
    gate-shift = <0>;  //0+REG_CKG_AESDMA_OFFSET
    glitch-shift = <4>;  //4+REG_CKG_AESDMA_OFFSET
    auto-enable = <0>;
};

CLK_sdio: CLK_sdio {
    #clock-cells = <0>;
    compatible = "sstar,composite-clock";
    clocks = <&CLK_utmi_192m_div4>,<&CLK_mpll_86m_div2>,<&CLK_utmi_160m_div4>,<&CLK_mpll_288m_div8>,<&CLK_utmi_160m_div5>,<&CLK_utmi_160m_div8>,<&CLK_xtali_12m>,<&CLK_xtali_12m_div40>;
    reg = <REG_CKG_SDIO_BASE 0x4>;
    mux-shift = <2>;  //2+REG_CKG_SDIO_OFFSET
    mux-width = <3>;
    gate-shift = <0>;  //0+REG_CKG_SDIO_OFFSET
    auto-enable = <0>;
};

CLK_sd: CLK_sd {
    #clock-cells = <0>;
    compatible = "sstar,composite-clock";
    clocks = <&CLK_utmi_192m_div4>,<&CLK_mpll_86m_div2>,<&CLK_utmi_160m_div4>,<&CLK_mpll_288m_div8>,<&CLK_utmi_160m_div5>,<&CLK_utmi_160m_div8>,<&CLK_xtali_12m>,<&CLK_xtali_12m_div40>;
    reg = <REG_CKG_SD_BASE 0x4>;
    mux-shift = <2>;  //2+REG_CKG_SD_OFFSET
    mux-width = <3>;
    gate-shift = <0>;  //0+REG_CKG_SD_OFFSET
    auto-enable = <0>;
};

CLK_ecc: CLK_ecc {
    #clock-cells = <0>;
    compatible = "sstar,composite-clock";
    clocks = <&CLK_utmi_160m>,<&CLK_mpll_216m_div2>,<&CLK_mpll_216m_div4>,<&CLK_xtali_12m>;
    reg = <REG_CKG_ECC_BASE 0x4>;
    mux-shift = <2>;  //2+REG_CKG_ECC_OFFSET
    mux-width = <2>;
    gate-shift = <0>;  //0+REG_CKG_ECC_OFFSET
};

CLK_isp: CLK_isp {
    #clock-cells = <0>;
    compatible = "sstar,composite-clock";
    clocks = <&CLK_upll_320m>,<&CLK_mpll_288m>,<&CLK_mpll_216m>,<&CLK_utmi_192m>,<&CLK_mpll_172m>,<&CLK_mpll_123m>,<&CLK_mpll_288m_div4>,<&CLK_upll_384m>;
    reg = <REG_CKG_ISP_BASE 0x4>;
    mux-shift = <10>;  //2+REG_CKG_ISP_OFFSET
    mux-width = <3>;
    gate-shift = <8>;  //0+REG_CKG_ISP_OFFSET
    auto-enable = <0>;
};

CLK_fclk1: CLK_fclk1 {
    #clock-cells = <0>;
    compatible = "sstar,composite-clock";
    clocks = <&CLK_utmi_480m>,<&CLK_mpll_432m>,<&CLK_upll_384m>,<&CLK_upll_320m>,<&CLK_mpll_288m>,<&CLK_utmi_240m>,<&CLK_mpll_172m>,<&CLK_mpll_123m>;
    reg = <REG_CKG_FCLK1_BASE 0x4>;
    mux-shift = <2>;  //2+REG_CKG_FCLK1_OFFSET
    mux-width = <3>;
    gate-shift = <0>;  //0+REG_CKG_FCLK1_OFFSET
    auto-enable = <0>;
};

CLK_odclk: CLK_odclk {
    #clock-cells = <0>;
    compatible = "sstar,composite-clock";
    clocks = <&CLK_mpll_86m>,<&CLK_mpll_86m_div2>,<&CLK_mpll_86m_div4>,<&CLK_lpll_clk>;
    reg = <REG_CKG_ODCLK_BASE 0x4>;
    mux-shift = <2>;  //2+REG_CKG_ODCLK_OFFSET
    mux-width = <2>;
    gate-shift = <0>;  //0+REG_CKG_ODCLK_OFFSET
    auto-enable = <0>;
};

CLK_dip: CLK_dip {
    #clock-cells = <0>;
    compatible = "sstar,composite-clock";
    clocks = <&CLK_utmi_480m>,<&CLK_mpll_432m>,<&CLK_upll_384m>,<&CLK_upll_320m>,<&CLK_mpll_288m>,<&CLK_utmi_240m>,<&CLK_mpll_172m>,<&CLK_mpll_123m>;
    reg = <REG_CKG_DIP_BASE 0x4>;
    mux-shift = <2>;  //2+REG_CKG_DIP_OFFSET
    mux-width = <3>;
    gate-shift = <0>;  //0+REG_CKG_DIP_OFFSET
    auto-enable = <0>;
};

CLK_emac_tx: CLK_emac_tx {
    #clock-cells = <0>;
    compatible = "sstar,composite-clock";
    clocks = <&CLK_eth_buf>,<&CLK_rmii_buf>;
    reg = <REG_CKG_EMAC_TX_BASE 0x4>;
    mux-shift = <2>;  //2+REG_CKG_EMAC_TX_OFFSET
    mux-width = <1>;
    gate-shift = <0>;  //0+REG_CKG_EMAC_TX_OFFSET
};

CLK_emac_rx: CLK_emac_rx {
    #clock-cells = <0>;
    compatible = "sstar,composite-clock";
    clocks = <&CLK_eth_buf>,<&CLK_rmii_buf>;
    reg = <REG_CKG_EMAC_RX_BASE 0x4>;
    mux-shift = <2>;  //2+REG_CKG_EMAC_RX_OFFSET
    mux-width = <1>;
    gate-shift = <0>;  //0+REG_CKG_EMAC_RX_OFFSET
};

CLK_emac_tx_ref: CLK_emac_tx_ref {
    #clock-cells = <0>;
    compatible = "sstar,composite-clock";
    clocks = <&CLK_rmii_buf>,<&CLK_VOID>;
    reg = <REG_CKG_EMAC_TX_REF_BASE 0x4>;
    mux-shift = <10>;  //2+REG_CKG_EMAC_TX_REF_OFFSET
    mux-width = <1>;
    gate-shift = <8>;  //0+REG_CKG_EMAC_TX_REF_OFFSET
};

CLK_emac_rx_ref: CLK_emac_rx_ref {
    #clock-cells = <0>;
    compatible = "sstar,composite-clock";
    clocks = <&CLK_rmii_buf>,<&CLK_VOID>;
    reg = <REG_CKG_EMAC_RX_REF_BASE 0x4>;
    mux-shift = <10>;  //2+REG_CKG_EMAC_RX_REF_OFFSET
    mux-width = <1>;
    gate-shift = <8>;  //0+REG_CKG_EMAC_RX_REF_OFFSET
};

CLK_ive: CLK_ive {
    #clock-cells = <0>;
    compatible = "sstar,composite-clock";
    clocks = <&CLK_mpll_216m>,<&CLK_mpll_172m>,<&CLK_mpll_123m>,<&CLK_mpll_86m>,<&CLK_mpll_288m>,<&CLK_upll_320m>,<&CLK_upll_384m>,<&CLK_VOID>;
    reg = <REG_CKG_IVE_BASE 0x4>;
    mux-shift = <10>;  //2+REG_CKG_IVE_OFFSET
    mux-width = <3>;
    gate-shift = <8>;  //0+REG_CKG_IVE_OFFSET
    auto-enable = <0>;
};

CLK_ldcfeye: CLK_ldcfeye {
    #clock-cells = <0>;
    compatible = "sstar,composite-clock";
    clocks = <&CLK_utmi_480m>,<&CLK_mpll_432m>,<&CLK_upll_384m>,<&CLK_upll_320m>,<&CLK_mpll_288m>,<&CLK_mpll_216m>,<&CLK_mpll_86m>,<&CLK_VOID>;
    reg = <REG_CKG_LDCFEYE_BASE 0x4>;
    mux-shift = <2>;  //2+REG_CKG_LDCFEYE_OFFSET
    mux-width = <3>;
    gate-shift = <0>;  //0+REG_CKG_LDCFEYE_OFFSET
    auto-enable = <0>;
};

CLK_live_pm: CLK_live_pm {
    #clock-cells = <0>;
    compatible = "sstar,composite-clock";
    clocks = <&CLK_xtali_12m>,<&CLK_rtc_32k>,<&CLK_VOID>,<&CLK_VOID>;
    reg = <REG_CKG_LIVE_PM_BASE 0x4>;
    mux-shift = <0>;  //0+REG_CKG_LIVE_PM_OFFSET
    mux-width = <2>;
    auto-enable = <0>;
};

CLK_mcu_pm_p1: CLK_mcu_pm_p1 {
    #clock-cells = <0>;
    compatible = "sstar,composite-clock";
    clocks = <&CLK_xtali_12m>,<&CLK_fro_div8>,<&CLK_rtc_32k>,<&CLK_fro_div2>;
    reg = <REG_CKG_MCU_PM_P1_BASE 0x4>;
    mux-shift = <2>;  //2+REG_CKG_MCU_PM_P1_OFFSET
    mux-width = <2>;
    gate-shift = <0>;  //0+REG_CKG_MCU_PM_P1_OFFSET
    auto-enable = <1>;
};


CLK_spi_pm: CLK_spi_pm {
    #clock-cells = <0>;
    compatible = "sstar,composite-clock";
    clocks = <&CLK_fro>,<&CLK_rtc_32k>,<&CLK_mpll_86m>,<&CLK_mpll_216m_div2>,<&CLK_xtali_12m>,<&CLK_fro_div2>,<&CLK_xtali_24m>,<&CLK_mpll_216m_div4>;
    reg = <REG_CKG_SPI_BASE 0x4>;
    mux-shift = <10>;  //2+REG_CKG_SPI_OFFSET
    mux-width = <3>;
    gate-shift = <8>;  //0+REG_CKG_SPI_OFFSET
    glitch-shift = <13>;  //5+REG_CKG_SPI_OFFSET
    auto-enable = <1>;
};

CLK_miic_pm: CLK_miic_pm {
    #clock-cells = <0>;
    compatible = "sstar,composite-clock";
    clocks = <&CLK_mpll_86m>,<&CLK_xtali_12m>,<&CLK_fro_div2>,<&CLK_rtc_32k>;
    reg = <REG_CKG_MIIC_BASE 0x4>;
    mux-shift = <14>;  //2+REG_CKG_MIIC_OFFSET
    mux-width = <2>;
    gate-shift = <12>;  //0+REG_CKG_MIIC_OFFSET
    auto-enable = <0>;
};

CLK_pm_sleep: CLK_pm_sleep {
    #clock-cells = <0>;
    compatible = "sstar,composite-clock";
    clocks = <&CLK_xtali_12m>,<&CLK_rtc_32k>,<&CLK_fro_div2>,<&CLK_VOID>;
    reg = <REG_CKG_PM_SLEEP_BASE 0x4>;
    mux-shift = <10>;  //0+REG_CKG_PM_SLEEP_OFFSET
    mux-width = <2>;
    auto-enable = <1>;
};

CLK_rtc: CLK_rtc {
    #clock-cells = <0>;
    compatible = "sstar,composite-clock";
    clocks = <&CLK_xtali_12m>,<&CLK_rtc_32k>,<&CLK_VOID>,<&CLK_VOID>;
    reg = <REG_CKG_RTC_BASE 0x4>;
    mux-shift = <2>;  //2+REG_CKG_RTC_OFFSET
    mux-width = <2>;
    gate-shift = <0>;  //0+REG_CKG_RTC_OFFSET
    auto-enable = <1>;
};

CLK_sar: CLK_sar {
    #clock-cells = <0>;
    compatible = "sstar,composite-clock";
    clocks = <&CLK_xtali_12m>,<&CLK_rtc_32k>,<&CLK_VOID>,<&CLK_VOID>;
    reg = <REG_CKG_SAR_BASE 0x4>;
    mux-shift = <7>;  //2+REG_CKG_SAR_OFFSET
    mux-width = <2>;
    gate-shift = <5>;  //0+REG_CKG_SAR_OFFSET
    auto-enable = <1>;
};

CLK_pir: CLK_pir {
    #clock-cells = <0>;
    compatible = "sstar,composite-clock";
    clocks = <&CLK_xtali_12m>,<&CLK_fro_div16>,<&CLK_fro_div8>,<&CLK_fro_div2>;
    reg = <REG_CKG_PIR_BASE 0x4>;
    mux-shift = <10>;  //2+REG_CKG_PIR_OFFSET
    mux-width = <2>;
    gate-shift = <8>;  //0+REG_CKG_PIR_OFFSET
    auto-enable = <0>;
};

CLK_pm_uart: CLK_pm_uart {
    #clock-cells = <0>;
    compatible = "sstar,composite-clock";
    clocks = <&CLK_xtali_12m>,<&CLK_rtc_32k>,<&CLK_mpll_216m_div2>,<&CLK_mpll_86m>;
    reg = <REG_CKG_PM_UART_BASE 0x4>;
    mux-shift = <2>;  //2+REG_CKG_PM_UART_OFFSET
    mux-width = <2>;
    gate-shift = <0>;  //0+REG_CKG_PM_UART_OFFSET
    auto-enable = <0>;
};

usclk: usclk {
    compatible = "usclk";
    clocks = <&CLK_RTC_CLK_32K>,
             <&CLK_VOID>,
             <&CLK_aesdma>,
             <&CLK_armpll_37p125m>,
             <&CLK_bdma>,
             <&CLK_bist>,
             <&CLK_bist_ipu_gp>,
             <&CLK_bist_pm>,
             <&CLK_bist_sc_gp>,
             <&CLK_bist_usb30_gp>,
             <&CLK_bist_vhe_gp>,
             <&CLK_cpupll_clk>,
             <&CLK_csi_mac_lptx_top_i_m00>,
             <&CLK_csi_mac_lptx_top_i_m01>,
             <&CLK_csi_mac_lptx_top_i_m1>,
             <&CLK_csi_mac_top_i_m00>,
             <&CLK_csi_mac_top_i_m01>,
             <&CLK_csi_mac_top_i_m1>,
             <&CLK_ddr_syn>,
             <&CLK_ddrpll_clk>,
             <&CLK_dip>,
             <&CLK_emac_ahb>,
             <&CLK_emac_testrx125_in_lan>,
             <&CLK_eth_buf>,
             <&CLK_fclk1>,
             <&CLK_fclk1_p>,
             <&CLK_fro>,
             <&CLK_fro_div16>,
             <&CLK_fro_div2>,
             <&CLK_fro_div8>,
             <&CLK_fuart>,
             <&CLK_fuart0_synth_in>,
             <&CLK_fuart0_synth_out>,
             <&CLK_ipu>,
             <&CLK_ipuff>,
             <&CLK_isp>,
             <&CLK_ive>,
             <&CLK_jpe>,
             <&CLK_ldcfeye>,
             <&CLK_live>,
             <&CLK_live_pm>,
             <&CLK_lpll_clk>,
             <&CLK_lpll_div2>,
             <&CLK_lpll_div4>,
             <&CLK_lpll_div8>,
             <&CLK_mcu>,
             <&CLK_mcu_p>,
             <&CLK_mcu_pm_p1>,
             <&CLK_mfe>,
             <&CLK_miic0>,
             <&CLK_miic1>,
             <&CLK_miic2>,
             <&CLK_miic_pm>,
             <&CLK_mipi1_tx_csi>,
             <&CLK_miu>,
             <&CLK_miu_boot>,
             <&CLK_miu_p>,
             <&CLK_miu_rec>,
             <&CLK_miu_sc_gp_p>,
             <&CLK_miu_vhe_gp_p>,
             <&CLK_miupll_clk>,
             <&CLK_mpll_123m>,
             <&CLK_mpll_123m_div2>,
             <&CLK_mpll_172m>,
             <&CLK_mpll_216m>,
             <&CLK_mpll_216m_div2>,
             <&CLK_mpll_216m_div4>,
             <&CLK_mpll_216m_div8>,
             <&CLK_mpll_288m>,
             <&CLK_mpll_288m_div2>,
             <&CLK_mpll_288m_div4>,
             <&CLK_mpll_288m_div8>,
             <&CLK_mpll_432m>,
             <&CLK_mpll_86m>,
             <&CLK_mpll_86m_div16>,
             <&CLK_mpll_86m_div2>,
             <&CLK_mpll_86m_div4>,
             <&CLK_mspi>,
             <&CLK_mspi0>,
             <&CLK_mspi0_p>,
             <&CLK_mspi1>,
             <&CLK_mspi1_p>,
             <&CLK_ns_top_i_m00>,
             <&CLK_ns_top_i_m01>,
             <&CLK_ns_top_i_m1>,
             <&CLK_odclk>,
             <&CLK_pir>,
             <&CLK_pm_riu_w_clk_in>,
             <&CLK_pm_sleep>,
             <&CLK_pm_uart>,
             <&CLK_pwm>,
             <&CLK_pwr_ctl>,
             <&CLK_riu_w_clk_hemcu_gp>,
             <&CLK_riu_w_clk_in>,
             <&CLK_riu_w_clk_mcu_if_gp>,
             <&CLK_riu_w_clk_mipi_if_gp>,
             <&CLK_riu_w_clk_sc_gp>,
             <&CLK_riu_w_clk_top>,
             <&CLK_riu_w_clk_vhe_gp>,
             <&CLK_riubrdg>,
             <&CLK_rmii_buf>,
             <&CLK_rtc>,
             <&CLK_rtc_32k>,
             <&CLK_sar>,
             <&CLK_sd>,
             <&CLK_sdio>,
             <&CLK_sdio_p>,
             <&CLK_spi_arb>,
             <&CLK_spi_flash>,
             <&CLK_spi_pm>,
             <&CLK_sr00_mclk>,
             <&CLK_sr01_mclk>,
             <&CLK_sr1_mclk>,
             <&CLK_tck_buf>,
             <&CLK_uart0>,
             <&CLK_uart1>,
             <&CLK_upll_320m>,
             <&CLK_upll_384m>,
             <&CLK_utmi>,
             <&CLK_utmi_160m>,
             <&CLK_utmi_160m_div4>,
             <&CLK_utmi_160m_div5>,
             <&CLK_utmi_160m_div8>,
             <&CLK_utmi_192m>,
             <&CLK_utmi_192m_div4>,
             <&CLK_utmi_240m>,
             <&CLK_utmi_480m>,
             <&CLK_ven_pll>,
             <&CLK_ven_pll_div6>,
             <&CLK_vhe>,
             <&CLK_xtali>,
             <&CLK_xtali_12m>,
             <&CLK_xtali_12m_div128>,
             <&CLK_xtali_12m_div16>,
             <&CLK_xtali_12m_div2>,
             <&CLK_xtali_12m_div4>,
             <&CLK_xtali_12m_div40>,
             <&CLK_xtali_12m_div64>,
             <&CLK_xtali_12m_div8>,
             <&CLK_xtali_24m>,
             <&CLK_xtali_sc_gp>;
    clock-count = <141>;
};
